# MK10D5 register map
Vendor: Freescale Semiconductor, Inc.; File version: 1.6
CPU: CM4 r0p1, little endian, no MPU, no FPU, 0x4 interrupt priority bits, 0x0 interrupts
Registers are 32-bit, read-write, reset 0x0 unless marked. A register's access mark holds for its fields unless they carry their own. Offsets are from the block's base; [hi:lo] are bit positions; 'fields as' and 'values as' point back to an identical list.

## FTFL — Flash Memory Interface
Base 0x40020000; register names take the prefix FTFL_
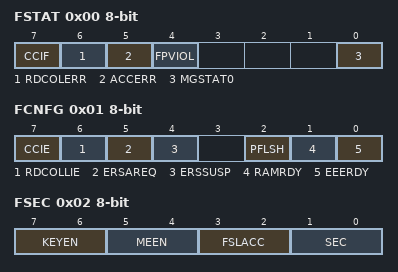
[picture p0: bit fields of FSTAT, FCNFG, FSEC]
0x00 FSTAT 8-bit — Flash Status Register
  [7] CCIF — Command Complete Interrupt Flag
    0=FTFL command or EEPROM file system operation in progress; 1=FTFL command or EEPROM file system operation has completed
  [6] RDCOLERR — FTFL Read Collision Error Flag
    0=No collision error detected; 1=Collision error detected
  [5] ACCERR — Flash Access Error Flag
    0=No access error detected; 1=Access error detected
  [4] FPVIOL — Flash Protection Violation Flag
    0=No protection violation detected; 1=Protection violation detected
  [0] MGSTAT0 ro — Memory Controller Command Completion Status Flag
0x01 FCNFG 8-bit — Flash Configuration Register
  [7] CCIE — Command Complete Interrupt Enable
    0=Command complete interrupt disabled; 1=Command complete interrupt enabled. An interrupt request is generated whenever the FSTAT[CCIF] flag is set.
  [6] RDCOLLIE — Read Collision Error Interrupt Enable
    0=Read collision error interrupt disabled; 1=Read collision error interrupt enabled. An interrupt request is generated whenever an FTFL read collision error is detected (see the description of FSTAT[RDCOLERR]).
  [5] ERSAREQ ro — Erase All Request
    0=No request or request complete; 1=Request to: run the Erase All Blocks command, verify the erased state, program the security byte in the Flash Configuration Field to the unsecure state, and release MCU security by setting the FSEC[SEC] field to the unsecure state
  [4] ERSSUSP — Erase Suspend
    0=No suspend requested; 1=Suspend the current Erase Flash Sector command execution
  [2] PFLSH ro — FTFL configuration
    0=FTFL configured for FlexMemory that supports data flash and/or EEPROM
  [1] RAMRDY ro — RAM Ready
    0=FlexRAM is not available for traditional RAM access; 1=FlexRAM is available as traditional RAM only; writes to the FlexRAM do not trigger EEPROM operations
  [0] EEERDY ro
    0=FlexRAM is not available for EEPROM operation; 1=FlexRAM is available for EEPROM operations where: reads from the FlexRAM return data previously written to the FlexRAM in EEPROM mode and writes to the FlexRAM clear EEERDY and launch an EEPROM operation to store the written data in the FlexRAM and EEPROM backup
0x02 FSEC 8-bit ro reset not defined — Flash Security Register
  [7:6] KEYEN — Backdoor Key Security Enable
    0=Backdoor key access disabled; 1=Backdoor key access disabled (preferred KEYEN state to disable backdoor key access); 2=Backdoor key access enabled; 3=Backdoor key access disabled
  [5:4] MEEN — Mass Erase Enable Bits
    0=Mass erase is enabled; 1=Mass erase is enabled; 2=Mass erase is disabled; 3=Mass erase is enabled
  [3:2] FSLACC — Freescale Failure Analysis Access Code
    0=Freescale factory access granted; 1=Freescale factory access denied; 2=Freescale factory access denied; 3=Freescale factory access granted
  [1:0] SEC — Flash Security
    0=MCU security status is secure; 1=MCU security status is secure; 2=MCU security status is unsecure (The standard shipping condition of the FTFL is unsecure.); 3=MCU security status is secure
0x03 FOPT 8-bit ro reset not defined — Flash Option Register
  [7:0] OPT — Nonvolatile Option
0x04 FCCOB3 8-bit — Flash Common Command Object Registers
  [7:0] CCOBn
0x05 FCCOB2 8-bit — Flash Common Command Object Registers
  [7:0] CCOBn
0x06 FCCOB1 8-bit — Flash Common Command Object Registers
  [7:0] CCOBn
0x07 FCCOB0 8-bit — Flash Common Command Object Registers
  [7:0] CCOBn
0x08 FCCOB7 8-bit — Flash Common Command Object Registers
  [7:0] CCOBn
0x09 FCCOB6 8-bit — Flash Common Command Object Registers
  [7:0] CCOBn
0x0A FCCOB5 8-bit — Flash Common Command Object Registers
  [7:0] CCOBn
0x0B FCCOB4 8-bit — Flash Common Command Object Registers
  [7:0] CCOBn
0x0C FCCOBB 8-bit — Flash Common Command Object Registers
  [7:0] CCOBn
0x0D FCCOBA 8-bit — Flash Common Command Object Registers
  [7:0] CCOBn
0x0E FCCOB9 8-bit — Flash Common Command Object Registers
  [7:0] CCOBn
0x0F FCCOB8 8-bit — Flash Common Command Object Registers
  [7:0] CCOBn
0x10 FPROT3 8-bit reset not defined — Program Flash Protection Registers
  [7:0] PROT — Program Flash Region Protect
    0=Program flash region is protected; 1=Program flash region is not protected
0x11 FPROT2 8-bit reset not defined — Program Flash Protection Registers
  fields as FPROT3
0x12 FPROT1 8-bit reset not defined — Program Flash Protection Registers
  fields as FPROT3
0x13 FPROT0 8-bit reset not defined — Program Flash Protection Registers
  fields as FPROT3
0x16 FEPROT 8-bit reset not defined — EEPROM Protection Register
  [7:0] EPROT — EEPROM Region Protect
    0=EEPROM region is protected; 1=EEPROM region is not protected
0x17 FDPROT 8-bit reset not defined — Data Flash Protection Register
  [7:0] DPROT — Data Flash Region Protect
    0=Data Flash region is protected; 1=Data Flash region is not protected
